VERSION ""

NS_ :

BS_:

BU_: Device Host
VAL_TABLE_ vtLanLinkStatus 0 "UpSlave" 1 "UpMaster" 2 "Down" 15 "Not Available" ;

BO_ 2650735102 CanInfo: 8 Device
 SG_ CanInfoType M : 0|8@1+ (1,0) [0|0] "" Vector__XXX
 SG_ CanSTxMsgRate m0 : 16|16@1+ (1,0) [0|0] "msg/s" Vector__XXX
 SG_ Can1TxMsgRate m1 : 16|16@1+ (1,0) [0|0] "msg/s" Vector__XXX
 SG_ Can2TxMsgRate m2 : 16|16@1+ (1,0) [0|0] "msg/s" Vector__XXX
 SG_ Can3TxMsgRate m3 : 16|16@1+ (1,0) [0|0] "msg/s" Vector__XXX
 SG_ Can4TxMsgRate m4 : 16|16@1+ (1,0) [0|0] "msg/s" Vector__XXX
 SG_ Can5TxMsgRate m5 : 16|16@1+ (1,0) [0|0] "msg/s" Vector__XXX
 SG_ Can6TxMsgRate m6 : 16|16@1+ (1,0) [0|0] "msg/s" Vector__XXX
 SG_ Can7TxMsgRate m7 : 16|16@1+ (1,0) [0|0] "msg/s" Vector__XXX
 SG_ Can8TxMsgRate m8 : 16|16@1+ (1,0) [0|0] "msg/s" Vector__XXX
 SG_ CanSRxMsgRate m0 : 32|16@1+ (1,0) [0|0] "msg/s" Vector__XXX
 SG_ Can1RxMsgRate m1 : 32|16@1+ (1,0) [0|0] "msg/s" Vector__XXX
 SG_ Can2RxMsgRate m2 : 32|16@1+ (1,0) [0|0] "msg/s" Vector__XXX
 SG_ Can3RxMsgRate m3 : 32|16@1+ (1,0) [0|0] "msg/s" Vector__XXX
 SG_ Can4RxMsgRate m4 : 32|16@1+ (1,0) [0|0] "msg/s" Vector__XXX
 SG_ Can5RxMsgRate m5 : 32|16@1+ (1,0) [0|0] "msg/s" Vector__XXX
 SG_ Can6RxMsgRate m6 : 32|16@1+ (1,0) [0|0] "msg/s" Vector__XXX
 SG_ Can7RxMsgRate m7 : 32|16@1+ (1,0) [0|0] "msg/s" Vector__XXX
 SG_ Can8RxMsgRate m8 : 32|16@1+ (1,0) [0|0] "msg/s" Vector__XXX
 SG_ CanSLostRxMRate m16 : 32|16@1+ (1,0) [0|0] "msg/s" Vector__XXX
 SG_ Can1LostRxMRate m17 : 32|16@1+ (1,0) [0|0] "msg/s" Vector__XXX
 SG_ Can2LostRxMRate m18 : 32|16@1+ (1,0) [0|0] "msg/s" Vector__XXX
 SG_ Can3LostRxMRate m19 : 32|16@1+ (1,0) [0|0] "msg/s" Vector__XXX
 SG_ Can4LostRxMRate m20 : 32|16@1+ (1,0) [0|0] "msg/s" Vector__XXX
 SG_ Can5LostRxMRate m21 : 32|16@1+ (1,0) [0|0] "msg/s" Vector__XXX
 SG_ Can6LostRxMRate m22 : 32|16@1+ (1,0) [0|0] "msg/s" Vector__XXX
 SG_ Can7LostRxMRate m23 : 32|16@1+ (1,0) [0|0] "msg/s" Vector__XXX
 SG_ Can8LostRxMRate m24 : 32|16@1+ (1,0) [0|0] "msg/s" Vector__XXX
 SG_ CanSErrorRate m0 : 48|16@1+ (1,0) [0|0] "err/s" Vector__XXX
 SG_ Can1ErrorRate m1 : 48|16@1+ (1,0) [0|0] "err/s" Vector__XXX
 SG_ Can2ErrorRate m2 : 48|16@1+ (1,0) [0|0] "err/s" Vector__XXX
 SG_ Can3ErrorRate m3 : 48|16@1+ (1,0) [0|0] "err/s" Vector__XXX
 SG_ Can4ErrorRate m4 : 48|16@1+ (1,0) [0|0] "err/s" Vector__XXX
 SG_ Can5ErrorRate m5 : 48|16@1+ (1,0) [0|0] "err/s" Vector__XXX
 SG_ Can6ErrorRate m6 : 48|16@1+ (1,0) [0|0] "err/s" Vector__XXX
 SG_ Can7ErrorRate m7 : 48|16@1+ (1,0) [0|0] "err/s" Vector__XXX
 SG_ Can8ErrorRate m8 : 48|16@1+ (1,0) [0|0] "err/s" Vector__XXX
 SG_ CanSLostTxMRate m16 : 48|16@1+ (1,0) [0|0] "msg/s" Vector__XXX
 SG_ Can1LostTxMRate m17 : 48|16@1+ (1,0) [0|0] "msg/s" Vector__XXX
 SG_ Can2LostTxMRate m18 : 48|16@1+ (1,0) [0|0] "msg/s" Vector__XXX
 SG_ Can3LostTxMRate m19 : 48|16@1+ (1,0) [0|0] "msg/s" Vector__XXX
 SG_ Can4LostTxMRate m20 : 48|16@1+ (1,0) [0|0] "msg/s" Vector__XXX
 SG_ Can5LostTxMRate m21 : 48|16@1+ (1,0) [0|0] "msg/s" Vector__XXX
 SG_ Can6LostTxMRate m22 : 48|16@1+ (1,0) [0|0] "msg/s" Vector__XXX
 SG_ Can7LostTxMRate m23 : 48|16@1+ (1,0) [0|0] "msg/s" Vector__XXX
 SG_ Can8LostTxMRate m24 : 48|16@1+ (1,0) [0|0] "msg/s" Vector__XXX

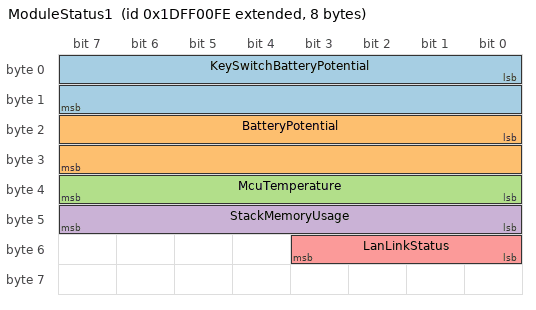
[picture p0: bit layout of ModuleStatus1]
BO_ 2650734846 ModuleStatus1: 8 Device
 SG_ KeySwitchBatteryPotential : 0|16@1+ (0.05,0) [0|3212.75] "V" Vector__XXX
 SG_ BatteryPotential : 16|16@1+ (0.05,0) [0|3212.75] "V" Vector__XXX
 SG_ McuTemperature : 32|8@1+ (1,-40) [-40|210] "C" Vector__XXX
 SG_ StackMemoryUsage : 40|8@1+ (0.4,0) [0|100] "%" Vector__XXX
 SG_ LanLinkStatus : 48|4@1+ (1,0) [0|0] "" Vector__XXX

CM_ "Module Health information messages
$File: //system_software/dbc/health_monitoring/0.36.0.0/Arrival_health.dbc $
$Change: 208863 $
$DateTime: 2023/11/10 13:11:00 $
$Revision: #1 $";
CM_ BO_ 2650735102 "Information about CAN bus message and error rate";
CM_ SG_ 2650735102 CanSLostRxMRate "All CANs lost RX messages due mailboxes overflow";
CM_ SG_ 2650735102 Can1LostRxMRate "CAN1 lost RX messages due mailboxes overflow";
CM_ SG_ 2650735102 Can2LostRxMRate "CAN2 lost RX messages due mailboxes overflow";
CM_ SG_ 2650735102 Can3LostRxMRate "CAN3 lost RX messages due mailboxes overflow";
CM_ SG_ 2650735102 Can4LostRxMRate "CAN4 lost RX messages due mailboxes overflow";
CM_ SG_ 2650735102 Can5LostRxMRate "CAN5 lost RX messages due mailboxes overflow";
CM_ SG_ 2650735102 Can6LostRxMRate "CAN6 lost RX messages due mailboxes overflow";
CM_ SG_ 2650735102 Can7LostRxMRate "CAN7 lost RX messages due mailboxes overflow";
CM_ SG_ 2650735102 Can8LostRxMRate "CAN8 lost RX messages due mailboxes overflow";
CM_ SG_ 2650735102 CanSLostTxMRate "All CANs lost TX messages due mailboxes overflow";
CM_ SG_ 2650735102 Can1LostTxMRate "CAN1 lost TX messages due mailboxes overflow";
CM_ SG_ 2650735102 Can2LostTxMRate "CAN2 lost TX messages due mailboxes overflow";
CM_ SG_ 2650735102 Can3LostTxMRate "CAN3 lost TX messages due mailboxes overflow";
CM_ SG_ 2650735102 Can4LostTxMRate "CAN4 lost TX messages due mailboxes overflow";
CM_ SG_ 2650735102 Can5LostTxMRate "CAN5 lost TX messages due mailboxes overflow";
CM_ SG_ 2650735102 Can6LostTxMRate "CAN6 lost TX messages due mailboxes overflow";
CM_ SG_ 2650735102 Can7LostTxMRate "CAN7 lost TX messages due mailboxes overflow";
CM_ SG_ 2650735102 Can8LostTxMRate "CAN8 lost TX messages due mailboxes overflow";
CM_ SG_ 2650734846 KeySwitchBatteryPotential "Battery potential measured at the input of the electronic control unit supplied through a key switch or similar switching device. (KL15 Voltage)";
CM_ SG_ 2650734846 BatteryPotential "This parameter measures the first source of battery potential as measured at the input of the ECU/actuator etc. coming from one or more batteries, irrespective of the distance between the component and the battery. (KL30)";
CM_ SG_ 2650734846 McuTemperature "MCU Core temperature. For sample TSENS value for SPC58xx";
CM_ SG_ 2650734846 StackMemoryUsage "The used capacity of stack memory area";
BA_DEF_  "BusType" STRING ;
BA_DEF_  "DBName" STRING ;
BA_DEF_ BO_  "GenMsgCycleTime" INT 0 65535;
BA_DEF_ BO_  "GenMsgILSupport" ENUM  "No","Yes";
BA_DEF_ BO_  "GenMsgRequestable" INT 0 1;
BA_DEF_ BO_  "GenMsgSendType" ENUM  "cyclic","NotUsed","NotUsed","NotUsed","NotUsed","NotUsed","NotUsed","IfActive","noMsgSendType";
BA_DEF_ SG_  "GenSigEVName" STRING ;
BA_DEF_ SG_  "GenSigILSupport" ENUM  "No","Yes";
BA_DEF_ SG_  "GenSigSendType" ENUM  "Cyclic","OnWrite","OnWriteWithRepetition","OnChange","OnChangeWithRepetition","IfActive","IfActiveWithRepetition","NoSigSendType";
BA_DEF_ SG_  "GenSigStartValue" FLOAT -3.4e+38 3.4e+38;
BA_DEF_ BU_  "NmStationAddress" INT 0 255;
BA_DEF_  "ProtocolType" STRING ;
BA_DEF_ SG_  "SPN" INT 0 524287;
BA_DEF_ SG_  "SigType" ENUM  "Default","Range","RangeSigned","ASCII","Discrete","Control","ReferencePGN","DTC","StringDelimiter","StringLength","StringLengthControl","MessageCounter","MessageChecksum";
BA_DEF_ BO_  "VFrameFormat" ENUM  "StandardCAN","ExtendedCAN","reserved","J1939PG";
BA_DEF_DEF_  "BusType" "CAN";
BA_DEF_DEF_  "DBName" "";
BA_DEF_DEF_  "GenMsgCycleTime" 0;
BA_DEF_DEF_  "GenMsgILSupport" "Yes";
BA_DEF_DEF_  "GenMsgRequestable" 1;
BA_DEF_DEF_  "GenMsgSendType" "noMsgSendType";
BA_DEF_DEF_  "GenSigEVName" "Env@Nodename_@Signame";
BA_DEF_DEF_  "GenSigILSupport" "Yes";
BA_DEF_DEF_  "GenSigSendType" "NoSigSendType";
BA_DEF_DEF_  "GenSigStartValue" 0;
BA_DEF_DEF_  "NmStationAddress" 254;
BA_DEF_DEF_  "ProtocolType" "";
BA_DEF_DEF_  "SPN" 0;
BA_DEF_DEF_  "SigType" "Default";
BA_DEF_DEF_  "VFrameFormat" "J1939PG";
BA_ "DBName" "Arrival_health";
BA_ "ProtocolType" "J1939";
BA_ "GenMsgCycleTime" BO_ 2650735102 1000;
BA_ "GenMsgSendType" BO_ 2650735102 0;
BA_ "GenMsgCycleTime" BO_ 2650734846 1000;
BA_ "GenMsgSendType" BO_ 2650734846 0;
BA_ "SPN" SG_ 2650735102 CanInfoType 516156;
BA_ "SPN" SG_ 2650735102 CanSTxMsgRate 516101;
BA_ "SigType" SG_ 2650735102 CanSTxMsgRate 1;
BA_ "SPN" SG_ 2650735102 Can1TxMsgRate 516104;
BA_ "SigType" SG_ 2650735102 Can1TxMsgRate 1;
BA_ "SPN" SG_ 2650735102 Can2TxMsgRate 516113;
BA_ "SigType" SG_ 2650735102 Can2TxMsgRate 1;
BA_ "SPN" SG_ 2650735102 Can3TxMsgRate 516119;
BA_ "SigType" SG_ 2650735102 Can3TxMsgRate 1;
BA_ "SPN" SG_ 2650735102 Can4TxMsgRate 516125;
BA_ "SigType" SG_ 2650735102 Can4TxMsgRate 1;
BA_ "SPN" SG_ 2650735102 Can5TxMsgRate 516131;
BA_ "SigType" SG_ 2650735102 Can5TxMsgRate 1;
BA_ "SPN" SG_ 2650735102 Can6TxMsgRate 516137;
BA_ "SigType" SG_ 2650735102 Can6TxMsgRate 1;
BA_ "SPN" SG_ 2650735102 Can7TxMsgRate 516143;
BA_ "SigType" SG_ 2650735102 Can7TxMsgRate 1;
BA_ "SPN" SG_ 2650735102 Can8TxMsgRate 516149;
BA_ "SigType" SG_ 2650735102 Can8TxMsgRate 1;
BA_ "SPN" SG_ 2650735102 CanSRxMsgRate 516102;
BA_ "SigType" SG_ 2650735102 CanSRxMsgRate 1;
BA_ "SPN" SG_ 2650735102 Can1RxMsgRate 516105;
BA_ "SigType" SG_ 2650735102 Can1RxMsgRate 1;
BA_ "SPN" SG_ 2650735102 Can2RxMsgRate 516114;
BA_ "SigType" SG_ 2650735102 Can2RxMsgRate 1;
BA_ "SPN" SG_ 2650735102 Can3RxMsgRate 516120;
BA_ "SigType" SG_ 2650735102 Can3RxMsgRate 1;
BA_ "SPN" SG_ 2650735102 Can4RxMsgRate 516126;
BA_ "SigType" SG_ 2650735102 Can4RxMsgRate 1;
BA_ "SPN" SG_ 2650735102 Can5RxMsgRate 516132;
BA_ "SigType" SG_ 2650735102 Can5RxMsgRate 1;
BA_ "SPN" SG_ 2650735102 Can6RxMsgRate 516138;
BA_ "SigType" SG_ 2650735102 Can6RxMsgRate 1;
BA_ "SPN" SG_ 2650735102 Can7RxMsgRate 516144;
BA_ "SigType" SG_ 2650735102 Can7RxMsgRate 1;
BA_ "SPN" SG_ 2650735102 Can8RxMsgRate 516150;
BA_ "SigType" SG_ 2650735102 Can8RxMsgRate 1;
BA_ "SPN" SG_ 2650735102 CanSLostRxMRate 516109;
BA_ "SigType" SG_ 2650735102 CanSLostRxMRate 1;
BA_ "SPN" SG_ 2650735102 Can1LostRxMRate 516112;
BA_ "SigType" SG_ 2650735102 Can1LostRxMRate 1;
BA_ "SPN" SG_ 2650735102 Can2LostRxMRate 516118;
BA_ "SigType" SG_ 2650735102 Can2LostRxMRate 1;
BA_ "SPN" SG_ 2650735102 Can3LostRxMRate 516124;
BA_ "SigType" SG_ 2650735102 Can3LostRxMRate 1;
BA_ "SPN" SG_ 2650735102 Can4LostRxMRate 516130;
BA_ "SigType" SG_ 2650735102 Can4LostRxMRate 1;
BA_ "SPN" SG_ 2650735102 Can5LostRxMRate 516136;
BA_ "SigType" SG_ 2650735102 Can5LostRxMRate 1;
BA_ "SPN" SG_ 2650735102 Can6LostRxMRate 516142;
BA_ "SigType" SG_ 2650735102 Can6LostRxMRate 1;
BA_ "SPN" SG_ 2650735102 Can7LostRxMRate 516148;
BA_ "SigType" SG_ 2650735102 Can7LostRxMRate 1;
BA_ "SPN" SG_ 2650735102 Can8LostRxMRate 516154;
BA_ "SigType" SG_ 2650735102 Can8LostRxMRate 1;
BA_ "SPN" SG_ 2650735102 CanSErrorRate 516103;
BA_ "SigType" SG_ 2650735102 CanSErrorRate 1;
BA_ "SPN" SG_ 2650735102 Can1ErrorRate 516106;
BA_ "SigType" SG_ 2650735102 Can1ErrorRate 1;
BA_ "SPN" SG_ 2650735102 Can2ErrorRate 516115;
BA_ "SigType" SG_ 2650735102 Can2ErrorRate 1;
BA_ "SPN" SG_ 2650735102 Can3ErrorRate 516121;
BA_ "SigType" SG_ 2650735102 Can3ErrorRate 1;
BA_ "SPN" SG_ 2650735102 Can4ErrorRate 516127;
BA_ "SigType" SG_ 2650735102 Can4ErrorRate 1;
BA_ "SPN" SG_ 2650735102 Can5ErrorRate 516133;
BA_ "SigType" SG_ 2650735102 Can5ErrorRate 1;
BA_ "SPN" SG_ 2650735102 Can6ErrorRate 516139;
BA_ "SigType" SG_ 2650735102 Can6ErrorRate 1;
BA_ "SPN" SG_ 2650735102 Can7ErrorRate 516145;
BA_ "SigType" SG_ 2650735102 Can7ErrorRate 1;
BA_ "SPN" SG_ 2650735102 Can8ErrorRate 516151;
BA_ "SigType" SG_ 2650735102 Can8ErrorRate 1;
BA_ "SPN" SG_ 2650735102 CanSLostTxMRate 516108;
BA_ "SigType" SG_ 2650735102 CanSLostTxMRate 1;
BA_ "SPN" SG_ 2650735102 Can1LostTxMRate 516111;
BA_ "SigType" SG_ 2650735102 Can1LostTxMRate 1;
BA_ "SPN" SG_ 2650735102 Can2LostTxMRate 516117;
BA_ "SigType" SG_ 2650735102 Can2LostTxMRate 1;
BA_ "SPN" SG_ 2650735102 Can3LostTxMRate 516123;
BA_ "SigType" SG_ 2650735102 Can3LostTxMRate 1;
BA_ "SPN" SG_ 2650735102 Can4LostTxMRate 516129;
BA_ "SigType" SG_ 2650735102 Can4LostTxMRate 1;
BA_ "SPN" SG_ 2650735102 Can5LostTxMRate 516135;
BA_ "SigType" SG_ 2650735102 Can5LostTxMRate 1;
BA_ "SPN" SG_ 2650735102 Can6LostTxMRate 516141;
BA_ "SigType" SG_ 2650735102 Can6LostTxMRate 1;
BA_ "SPN" SG_ 2650735102 Can7LostTxMRate 516147;
BA_ "SigType" SG_ 2650735102 Can7LostTxMRate 1;
BA_ "SPN" SG_ 2650735102 Can8LostTxMRate 516153;
BA_ "SigType" SG_ 2650735102 Can8LostTxMRate 1;
BA_ "SPN" SG_ 2650734846 KeySwitchBatteryPotential 158;
BA_ "SigType" SG_ 2650734846 KeySwitchBatteryPotential 1;
BA_ "SPN" SG_ 2650734846 BatteryPotential 168;
BA_ "SigType" SG_ 2650734846 BatteryPotential 1;
BA_ "GenSigStartValue" SG_ 2650734846 McuTemperature 40;
BA_ "SPN" SG_ 2650734846 McuTemperature 516100;
BA_ "SigType" SG_ 2650734846 McuTemperature 1;
BA_ "SPN" SG_ 2650734846 StackMemoryUsage 516155;
BA_ "SigType" SG_ 2650734846 StackMemoryUsage 1;
BA_ "SPN" SG_ 2650734846 LanLinkStatus 516157;
VAL_ 2650735102 CanInfoType 0 "CANS_Stats" 1 "CAN1_Stats" 2 "CAN2_Stats" 3 "CAN3_Stats" 4 "CAN4_Stats" 5 "CAN5_Stats" 6 "CAN6_Stats" 7 "CAN7_Stats" 8 "CAN8_Stats" 16 "CANS_Lost" 17 "CAN1_Lost" 18 "CAN2_Lost" 19 "CAN3_Lost" 20 "CAN4_Lost" 21 "CAN5_Lost" 22 "CAN6_Lost" 23 "CAN7_Lost" 24 "CAN8_Lost" 255 "Not Available" ;
VAL_ 2650734846 LanLinkStatus 0 "Down" 1 "UpSlave" 2 "UpMaster" 14 "Error" 15 "Not Available" ;
